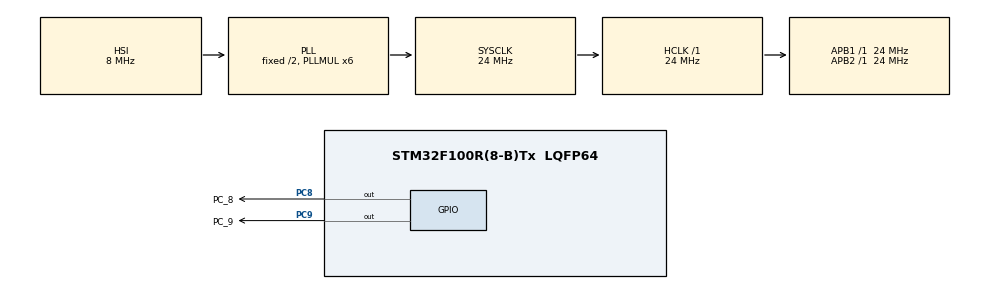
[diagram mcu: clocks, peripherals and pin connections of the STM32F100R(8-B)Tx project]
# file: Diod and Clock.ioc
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Mcu.Family=STM32F1
Mcu.Name=STM32F100R(8-B)Tx
Mcu.Package=LQFP64
NVIC.PriorityGroup=NVIC_PRIORITYGROUP_4
PA13.Mode=Serial_Wire
PA13.Signal=SYS_JTMS-SWDIO
PA14.Mode=Serial_Wire
PA14.Signal=SYS_JTCK-SWCLK
PC14-OSC32_IN.Mode=LSE-External-Oscillator
PC14-OSC32_IN.Signal=RCC_OSC32_IN
PC15-OSC32_OUT.Mode=LSE-External-Oscillator
PC15-OSC32_OUT.Signal=RCC_OSC32_OUT
PC8.GPIO_Label=PC_8
PC8.Signal=GPIO_Output
PC9.GPIO_Label=PC_9
PC9.Signal=GPIO_Output
PD0-OSC_IN.Mode=HSE-External-Oscillator
PD0-OSC_IN.Signal=RCC_OSC_IN
PD1-OSC_OUT.Mode=HSE-External-Oscillator
PD1-OSC_OUT.Signal=RCC_OSC_OUT
ProjectManager.HeapSize=0x200
ProjectManager.StackSize=0x400
ProjectManager.TargetToolchain=STM32CubeIDE
RCC.AHBFreq_Value=24000000
RCC.APB1Freq_Value=24000000
RCC.APB1TimFreq_Value=24000000
RCC.APB2Freq_Value=24000000
RCC.APB2TimFreq_Value=24000000
RCC.HCLKFreq_Value=24000000
RCC.PLLMUL=RCC_PLL_MUL6
RCC.RTCClockSelection=RCC_RTCCLKSOURCE_LSE
RCC.SYSCLKFreq_VALUE=24000000
RCC.SYSCLKSource=RCC_SYSCLKSOURCE_PLLCLK
VP_RTC_VS_RTC_Activate.Mode=RTC_Enabled
VP_RTC_VS_RTC_Calendar.Mode=RTC_Calendar
board=custom

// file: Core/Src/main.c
/* USER CODE BEGIN Header */
/**
  ******************************************************************************
  * @file           : main.c
  * @brief          : Main program body
  ******************************************************************************
  * @attention
  *
  * Copyright (c) 2022 STMicroelectronics.
  * All rights reserved.
  *
  * This software is licensed under terms that can be found in the LICENSE file
  * in the root directory of this software component.
  * If no LICENSE file comes with this software, it is provided AS-IS.
  *
  ******************************************************************************
  */
/* USER CODE END Header */
#include "main.h"

/* USER CODE BEGIN Includes */

RTC_TimeTypeDef TIME;
RTC_DateTypeDef DATE;

/* USER CODE END Includes */

RTC_HandleTypeDef hrtc;

void SystemClock_Config(void);
static void MX_GPIO_Init(void);
static void MX_RTC_Init(void);

int main(void)
{

  /* MCU Configuration--------------------------------------------------------*/

  /* Reset of all peripherals, Initializes the Flash interface and the Systick. */
  HAL_Init();

  /* Configure the system clock */
  SystemClock_Config();

  /* Initialize all configured peripherals */
  MX_GPIO_Init();
  MX_RTC_Init();
  /* USER CODE BEGIN 2 */

 /* if(TIME.Seconds == 14)

   {

  	 HAL_GPIO_WritePin(GPIOC, GPIO_PIN_8, GPIO_PIN_SET);
   }

   if(TIME.Seconds == 15)

   {

  	 HAL_GPIO_WritePin(GPIOC, GPIO_PIN_8, GPIO_PIN_RESET);
   }
*/
  /* USER CODE END 2 */

  /* Infinite loop */
  /* USER CODE BEGIN WHILE */
  while (1)
  {

	  // HAL_RTC_GetTime(&hrtc, &TIME, RTC_FORMAT_BIN);
		//  HAL_RTC_SetDate(&hrtc, &DATE, RTC_FORMAT_BIN);
    /* USER CODE END WHILE */

  }
}

void SystemClock_Config(void)
{
  RCC_OscInitTypeDef RCC_OscInitStruct = {0};
  RCC_ClkInitTypeDef RCC_ClkInitStruct = {0};
  RCC_PeriphCLKInitTypeDef PeriphClkInit = {0};

  /** Initializes the RCC Oscillators according to the specified parameters
  * in the RCC_OscInitTypeDef structure.
  */
  RCC_OscInitStruct.OscillatorType = RCC_OSCILLATORTYPE_HSI|RCC_OSCILLATORTYPE_LSE;
  RCC_OscInitStruct.LSEState = RCC_LSE_ON;
  RCC_OscInitStruct.HSIState = RCC_HSI_ON;
  RCC_OscInitStruct.HSICalibrationValue = RCC_HSICALIBRATION_DEFAULT;
  RCC_OscInitStruct.PLL.PLLState = RCC_PLL_ON;
  RCC_OscInitStruct.PLL.PLLSource = RCC_PLLSOURCE_HSI_DIV2;
  RCC_OscInitStruct.PLL.PLLMUL = RCC_PLL_MUL6;
  if (HAL_RCC_OscConfig(&RCC_OscInitStruct) != HAL_OK)
  {
    Error_Handler();
  }

  /** Initializes the CPU, AHB and APB buses clocks
  */
  RCC_ClkInitStruct.ClockType = RCC_CLOCKTYPE_HCLK|RCC_CLOCKTYPE_SYSCLK
                              |RCC_CLOCKTYPE_PCLK1|RCC_CLOCKTYPE_PCLK2;
  RCC_ClkInitStruct.SYSCLKSource = RCC_SYSCLKSOURCE_PLLCLK;
  RCC_ClkInitStruct.AHBCLKDivider = RCC_SYSCLK_DIV1;
  RCC_ClkInitStruct.APB1CLKDivider = RCC_HCLK_DIV1;
  RCC_ClkInitStruct.APB2CLKDivider = RCC_HCLK_DIV1;

  if (HAL_RCC_ClockConfig(&RCC_ClkInitStruct, FLASH_LATENCY_0) != HAL_OK)
  {
    Error_Handler();
  }
  PeriphClkInit.PeriphClockSelection = RCC_PERIPHCLK_RTC;
  PeriphClkInit.RTCClockSelection = RCC_RTCCLKSOURCE_LSE;
  if (HAL_RCCEx_PeriphCLKConfig(&PeriphClkInit) != HAL_OK)
  {
    Error_Handler();
  }
}

static void MX_RTC_Init(void)
{

  RTC_TimeTypeDef sTime = {0};
  RTC_DateTypeDef DateToUpdate = {0};

  /** Initialize RTC Only
  */
  hrtc.Instance = RTC;
  hrtc.Init.AsynchPrediv = RTC_AUTO_1_SECOND;
  hrtc.Init.OutPut = RTC_OUTPUTSOURCE_ALARM;
  if (HAL_RTC_Init(&hrtc) != HAL_OK)
  {
    Error_Handler();
  }

  /** Initialize RTC and set the Time and Date
  */
  sTime.Hours = 0x0;
  sTime.Minutes = 0x0;
  sTime.Seconds = 0x0;

  if (HAL_RTC_SetTime(&hrtc, &sTime, RTC_FORMAT_BCD) != HAL_OK)
  {
    Error_Handler();
  }
  DateToUpdate.WeekDay = RTC_WEEKDAY_MONDAY;
  DateToUpdate.Month = RTC_MONTH_JANUARY;
  DateToUpdate.Date = 0x1;
  DateToUpdate.Year = 0x0;

  if (HAL_RTC_SetDate(&hrtc, &DateToUpdate, RTC_FORMAT_BCD) != HAL_OK)
  {
    Error_Handler();
  }

}

static void MX_GPIO_Init(void)
{
  GPIO_InitTypeDef GPIO_InitStruct = {0};

  /* GPIO Ports Clock Enable */
  __HAL_RCC_GPIOC_CLK_ENABLE();
  __HAL_RCC_GPIOD_CLK_ENABLE();
  __HAL_RCC_GPIOA_CLK_ENABLE();

  /*Configure GPIO pin Output Level */
  HAL_GPIO_WritePin(GPIOC, PC_8_Pin|PC_9_Pin, GPIO_PIN_RESET);

  /*Configure GPIO pins : PC_8_Pin PC_9_Pin */
  GPIO_InitStruct.Pin = PC_8_Pin|PC_9_Pin;
  GPIO_InitStruct.Mode = GPIO_MODE_OUTPUT_PP;
  GPIO_InitStruct.Pull = GPIO_NOPULL;
  GPIO_InitStruct.Speed = GPIO_SPEED_FREQ_LOW;
  HAL_GPIO_Init(GPIOC, &GPIO_InitStruct);

}

void Error_Handler(void)
{
  __disable_irq();
  while (1)
  {
  }
}
